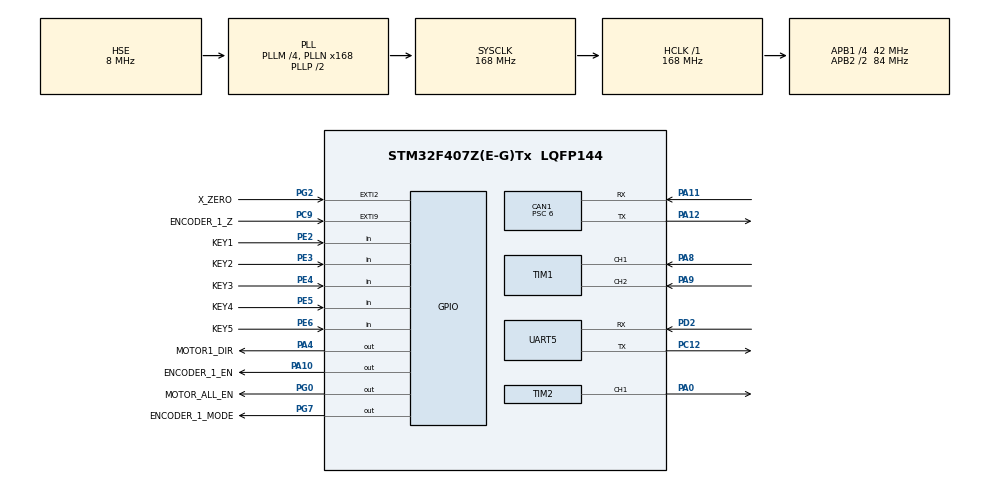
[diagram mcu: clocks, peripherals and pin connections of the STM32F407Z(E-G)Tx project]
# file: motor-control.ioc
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CAN1.ABOM=ENABLE
CAN1.AWUM=ENABLE
CAN1.BS1=CAN_BS1_10TQ
CAN1.BS2=CAN_BS2_3TQ
CAN1.CalculateBaudRate=500000
CAN1.CalculateTimeBit=2000
CAN1.CalculateTimeQuantum=142.85714285714286
CAN1.Prescaler=6
Mcu.Family=STM32F4
Mcu.Name=STM32F407Z(E-G)Tx
Mcu.Package=LQFP144
NVIC.CAN1_RX0_IRQn=true\:0\:0\:false\:false\:true\:true\:true\:true
NVIC.CAN1_RX1_IRQn=true\:0\:0\:false\:false\:true\:true\:true\:true
NVIC.CAN1_SCE_IRQn=true\:0\:0\:false\:false\:true\:true\:true\:true
NVIC.CAN1_TX_IRQn=true\:0\:0\:false\:false\:true\:true\:true\:true
NVIC.EXTI2_IRQn=true\:0\:0\:false\:false\:true\:true\:true\:true
NVIC.EXTI9_5_IRQn=true\:0\:0\:false\:false\:true\:true\:true\:true
NVIC.PriorityGroup=NVIC_PRIORITYGROUP_4
NVIC.TIM1_TRG_COM_TIM11_IRQn=true\:0\:0\:false\:false\:true\:true\:true\:true
NVIC.TIM2_IRQn=true\:0\:0\:false\:false\:true\:true\:true\:true
NVIC.TIM3_IRQn=true\:0\:0\:false\:false\:true\:true\:true\:true
PA0-WKUP.Signal=S_TIM2_CH1_ETR
PA10.GPIO_Label=ENCODER_1_EN
PA10.Signal=GPIO_Output
PA11.Mode=CAN_Activate
PA11.Signal=CAN1_RX
PA12.Mode=CAN_Activate
PA12.Signal=CAN1_TX
PA13.Mode=Serial_Wire
PA13.Signal=SYS_JTMS-SWDIO
PA14.Mode=Serial_Wire
PA14.Signal=SYS_JTCK-SWCLK
PA4.GPIO_Label=MOTOR1_DIR
PA4.Signal=GPIO_Output
PA8.Signal=S_TIM1_CH1
PA9.Signal=S_TIM1_CH2
PC12.Mode=Asynchronous
PC12.Signal=UART5_TX
PC14-OSC32_IN.Mode=LSE-External-Oscillator
PC14-OSC32_IN.Signal=RCC_OSC32_IN
PC15-OSC32_OUT.Mode=LSE-External-Oscillator
PC15-OSC32_OUT.Signal=RCC_OSC32_OUT
PC9.GPIO_Label=ENCODER_1_Z
PC9.GPIO_PuPd=GPIO_PULLDOWN
PC9.Signal=GPXTI9
PD2.Mode=Asynchronous
PD2.Signal=UART5_RX
PE2.GPIO_Label=KEY1
PE2.GPIO_PuPd=GPIO_PULLUP
PE2.Signal=GPIO_Input
PE3.GPIO_Label=KEY2
PE3.GPIO_PuPd=GPIO_PULLUP
PE3.Signal=GPIO_Input
PE4.GPIO_Label=KEY3
PE4.GPIO_PuPd=GPIO_PULLUP
PE4.Signal=GPIO_Input
PE5.GPIO_Label=KEY4
PE5.GPIO_PuPd=GPIO_PULLUP
PE5.Signal=GPIO_Input
PE6.GPIO_Label=KEY5
PE6.GPIO_PuPd=GPIO_PULLUP
PE6.Signal=GPIO_Input
PG0.GPIO_Label=MOTOR_ALL_EN
PG0.Signal=GPIO_Output
PG2.GPIO_Label=X_ZERO
PG2.GPIO_ModeDefaultEXTI=GPIO_MODE_IT_FALLING
PG2.GPIO_PuPd=GPIO_PULLUP
PG2.Signal=GPXTI2
PG7.GPIO_Label=ENCODER_1_MODE
PG7.GPIO_Speed=GPIO_SPEED_FREQ_HIGH
PG7.Signal=GPIO_Output
PH0-OSC_IN.Mode=HSE-External-Oscillator
PH0-OSC_IN.Signal=RCC_OSC_IN
PH1-OSC_OUT.Mode=HSE-External-Oscillator
PH1-OSC_OUT.Signal=RCC_OSC_OUT
ProjectManager.HeapSize=0x1400
ProjectManager.StackSize=0x800
ProjectManager.TargetToolchain=MDK-ARM V5.32
RCC.48MHZClocksFreq_Value=84000000
RCC.AHBFreq_Value=168000000
RCC.APB1CLKDivider=RCC_HCLK_DIV4
RCC.APB1Freq_Value=42000000
RCC.APB1TimFreq_Value=84000000
RCC.APB2CLKDivider=RCC_HCLK_DIV2
RCC.APB2Freq_Value=84000000
RCC.APB2TimFreq_Value=168000000
RCC.CortexFreq_Value=168000000
RCC.HCLKFreq_Value=168000000
RCC.HSE_VALUE=8000000
RCC.HSI_VALUE=16000000
RCC.PLLM=4
RCC.PLLN=168
RCC.PLLSourceVirtual=RCC_PLLSOURCE_HSE
RCC.SYSCLKFreq_VALUE=168000000
RCC.SYSCLKSource=RCC_SYSCLKSOURCE_PLLCLK
RCC.VCOOutputFreq_Value=336000000
SH.S_TIM1_CH1.0=TIM1_CH1,Encoder_Interface
SH.S_TIM1_CH2.0=TIM1_CH2,Encoder_Interface
SH.S_TIM2_CH1_ETR.0=TIM2_CH1,PWM Generation1 CH1
TIM1.EncoderMode=TIM_ENCODERMODE_TI12
TIM11.Period=1000-1
TIM11.Prescaler=84-1
TIM2.AutoReloadPreload=TIM_AUTORELOAD_PRELOAD_ENABLE
TIM2.Channel-PWM\ Generation1\ CH1=TIM_CHANNEL_1
TIM2.Period=1000-1
TIM2.Prescaler=84-1
TIM2.Pulse-PWM\ Generation1\ CH1=500
TIM3.Period=999
TIM3.Prescaler=83
UART5.VirtualMode=Asynchronous
VP_TIM11_VS_ClockSourceINT.Mode=Enable_Timer
VP_TIM2_VS_ClockSourceINT.Mode=Internal
VP_TIM3_VS_ClockSourceINT.Mode=Internal
board=custom

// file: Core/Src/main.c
/* USER CODE BEGIN Header */
/**
  ******************************************************************************
  * @file           : main.c
  * @brief          : Main program body
  ******************************************************************************
  * @attention
  *
  * Copyright (c) 2026 STMicroelectronics.
  * All rights reserved.
  *
  * This software is licensed under terms that can be found in the LICENSE file
  * in the root directory of this software component.
  * If no LICENSE file comes with this software, it is provided AS-IS.
  *
  ******************************************************************************
  */
/* USER CODE END Header */
#include "main.h"
#include "can.h"
#include "tim.h"
#include "usart.h"
#include "gpio.h"

/* USER CODE BEGIN Includes */
#include "App_Main.h"
/* USER CODE END Includes */

void SystemClock_Config(void);

int main(void)
{

  /* MCU Configuration--------------------------------------------------------*/

  /* Reset of all peripherals, Initializes the Flash interface and the Systick. */
  HAL_Init();

  /* Configure the system clock */
  SystemClock_Config();

  /* Initialize all configured peripherals */
  MX_GPIO_Init();
  MX_UART5_Init();
  MX_TIM2_Init();
  MX_TIM1_Init();
  MX_TIM3_Init();
  MX_CAN1_Init();
  MX_TIM11_Init();
  /* USER CODE BEGIN 2 */

  App_main();
  /* USER CODE END 2 */

  /* Infinite loop */
  while (1)
  {

  }
}

void SystemClock_Config(void)
{
  RCC_OscInitTypeDef RCC_OscInitStruct = {0};
  RCC_ClkInitTypeDef RCC_ClkInitStruct = {0};

  /** Configure the main internal regulator output voltage
  */
  __HAL_RCC_PWR_CLK_ENABLE();
  __HAL_PWR_VOLTAGESCALING_CONFIG(PWR_REGULATOR_VOLTAGE_SCALE1);

  /** Initializes the RCC Oscillators according to the specified parameters
  * in the RCC_OscInitTypeDef structure.
  */
  RCC_OscInitStruct.OscillatorType = RCC_OSCILLATORTYPE_HSE;
  RCC_OscInitStruct.HSEState = RCC_HSE_ON;
  RCC_OscInitStruct.PLL.PLLState = RCC_PLL_ON;
  RCC_OscInitStruct.PLL.PLLSource = RCC_PLLSOURCE_HSE;
  RCC_OscInitStruct.PLL.PLLM = 4;
  RCC_OscInitStruct.PLL.PLLN = 168;
  RCC_OscInitStruct.PLL.PLLP = RCC_PLLP_DIV2;
  RCC_OscInitStruct.PLL.PLLQ = 4;
  if (HAL_RCC_OscConfig(&RCC_OscInitStruct) != HAL_OK)
  {
    Error_Handler();
  }

  /** Initializes the CPU, AHB and APB buses clocks
  */
  RCC_ClkInitStruct.ClockType = RCC_CLOCKTYPE_HCLK|RCC_CLOCKTYPE_SYSCLK
                              |RCC_CLOCKTYPE_PCLK1|RCC_CLOCKTYPE_PCLK2;
  RCC_ClkInitStruct.SYSCLKSource = RCC_SYSCLKSOURCE_PLLCLK;
  RCC_ClkInitStruct.AHBCLKDivider = RCC_SYSCLK_DIV1;
  RCC_ClkInitStruct.APB1CLKDivider = RCC_HCLK_DIV4;
  RCC_ClkInitStruct.APB2CLKDivider = RCC_HCLK_DIV2;

  if (HAL_RCC_ClockConfig(&RCC_ClkInitStruct, FLASH_LATENCY_5) != HAL_OK)
  {
    Error_Handler();
  }
}

void Error_Handler(void)
{
  __disable_irq();
  while (1)
  {
  }
}
